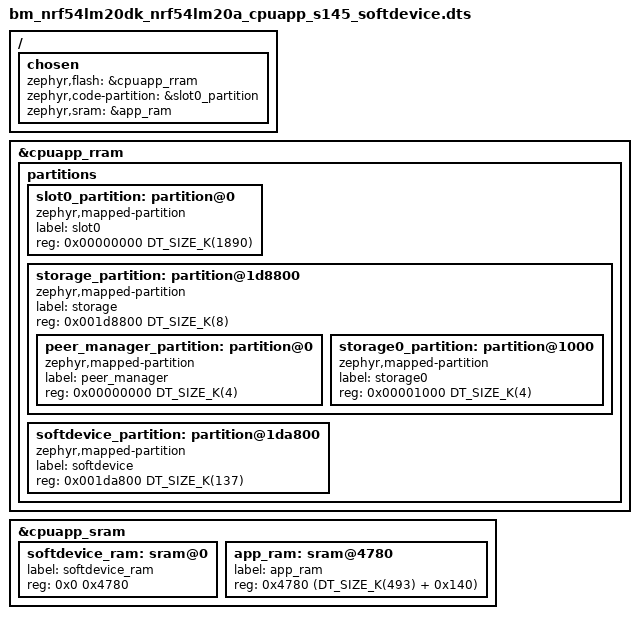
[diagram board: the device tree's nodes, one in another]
/*
 * Copyright (c) 2026 Nordic Semiconductor ASA
 *
 * SPDX-License-Identifier: LicenseRef-Nordic-5-Clause
 */

/dts-v1/;

#include <nordic/nrf54lm20a_cpuapp.dtsi>
#include "bm_nrf54lm20dk_nrf54lm20a_cpuapp_common.dtsi"

/ {
	chosen {
		zephyr,flash = &cpuapp_rram;
		zephyr,code-partition = &slot0_partition;
		zephyr,sram = &app_ram;
	};
};

&cpuapp_rram {
	status = "okay";

	partitions {
		#address-cells = <1>;
		#size-cells = <1>;
		ranges;

		slot0_partition: partition@0 {
			compatible = "zephyr,mapped-partition";
			label = "slot0";
			reg = <0x00000000 DT_SIZE_K(1890)>;
		};

		storage_partition: partition@1d8800 {
			compatible = "zephyr,mapped-partition";
			label = "storage";
			reg = <0x001d8800 DT_SIZE_K(8)>;
			ranges = <0x0 0x1d8800 DT_SIZE_K(8)>;
			#address-cells = <1>;
			#size-cells = <1>;

			peer_manager_partition: partition@0 {
				compatible = "zephyr,mapped-partition";
				label = "peer_manager";
				reg = <0x00000000 DT_SIZE_K(4)>;
			};

			storage0_partition: partition@1000 {
				compatible = "zephyr,mapped-partition";
				label = "storage0";
				reg = <0x00001000 DT_SIZE_K(4)>;
			};
		};

		softdevice_partition: partition@1da800 {
			compatible = "zephyr,mapped-partition";
			label = "softdevice";
			reg = <0x001da800 DT_SIZE_K(137)>;
		};
	};
};

&cpuapp_sram {
	status = "okay";

	softdevice_ram: sram@0 {
		label = "softdevice_ram";
		reg = <0x0 0x4780>;
	};

	app_ram: sram@4780 {
		label = "app_ram";
		reg = <0x4780 (DT_SIZE_K(493) + 0x140)>;
	};
};
